# haltium_sysctrl register map
Vendor: Nordic Semiconductor; Series: nRFHaltium; File version: 1
Registers are 32-bit, read-write, reset 0x0 unless marked. A register's access mark holds for its fields unless they carry their own. Offsets are from the block's base; [hi:lo] are bit positions; {n}, {i} and the like mark numbered series.

## RAMC110_S — RAM Controller 0
Base 0x5F083000
Same registers: RAMC111_S 0x5F084000, RAMC112_S 0x5F08A000, RAMC113_S 0x5F08B000, RAMC120_S 0x5F8C3000, RAMC121_S 0x5F8C4000, RAMC130_S 0x5F903000, RAMC131_S 0x5F904000
0x500 WAITSTATES — Waitstates for read operations.
  [0] WAITSTATES — Number of waitstates for a read from the RAM.

## SHA3_S — CRACEN
Base 0x5F088000
0x100 EVENTS_CRYPTOMASTER — Event indicating that interrupt triggered at Cryptomaster
  [0] EVENTS_CRYPTOMASTER
    0=NotGenerated (Event not generated); 1=Generated (Event generated)
0x300 INTEN — Enable or disable interrupt
  [0] CRYPTOMASTER — Enable or disable interrupt for event CRYPTOMASTER
    0=Disabled; 1=Enabled
0x304 INTENSET — Enable interrupt
  [0] CRYPTOMASTER — Write '1' to enable interrupt for event CRYPTOMASTER
    on read: 0=Disabled (Read: Disabled); 1=Enabled (Read: Enabled) | on write: 1=Set (Enable)
0x308 INTENCLR — Disable interrupt
  [0] CRYPTOMASTER — Write '1' to disable interrupt for event CRYPTOMASTER
    on read: 0=Disabled (Read: Disabled); 1=Enabled (Read: Enabled) | on write: 1=Clear (Disable)
0x30C INTPEND ro — Pending interrupts
  [0] CRYPTOMASTER — Read pending status of interrupt for event CRYPTOMASTER
    on read: 0=NotPending (Read: Not pending); 1=Pending (Read: Pending)
0x400 ENABLE — Enable CRACEN peripheral modules.
  [0] CRYPTOMASTER — Enable cryptomaster
    0=Disabled (Cryptomaster disabled.); 1=Enabled (Cryptomaster enabled.)

## PCGCS110_S — PCGCSlave 0
Base 0x5F08E000
Same registers: PCGCS120_S 0x5F8EA000, PCGCS121_S 0x5F8EB000, PCGCS122_S 0x5F8EC000, PCGCS130_S 0x5F90E000, PCGCS131_S 0x5F93C000, PCGCS132_S 0x5F94E000, PCGCS133_S 0x5F98E000, PCGCS134_S 0x5F99E000, PCGCS135_S 0x5F9AE000, PCGCS136_S 0x5F9BE000, PCGCS137_S 0x5F9CE000, PCGCS138_S 0x5F9DE000
0x78 TRIGZEROPENALTY — Trigger zero penalty
  [0] TRIGGER
    1=Enable (Trigger zero penalty)
0x7C TRIGFULLPENALTY — Trigger full penalty
  [0] TRIGGER
    1=Enable (Trigger full penalty)
{0xC00+4i} PENALTY[{i}] (i=0..1) — Description collection: Penalty level for power/clock pair n
  [7:0] PENALTY — Penalty level
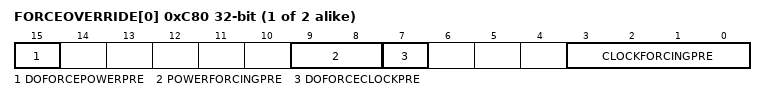
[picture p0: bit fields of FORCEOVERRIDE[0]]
{0xC80+4i} FORCEOVERRIDE[{i}] (i=0..1) — Description collection: Force override of power/clock pair n
  [15] DOFORCEPOWERPRE, [9:8] POWERFORCINGPRE, [7] DOFORCECLOCKPRE, [3:0] CLOCKFORCINGPRE

## PCGCM110_S — PCGC Master 0
Base 0x5F08F000
Same registers: PCGCM120_S 0x5F8CF000, PCGCM121_S 0x5F8ED000, PCGCM130_S 0x5F93D000, PCGCM131_S 0x5F93F000, PCGCM132_S 0x5F94F000, PCGCM133_S 0x5F98F000, PCGCM134_S 0x5F99F000, PCGCM135_S 0x5F9AF000, PCGCM136_S 0x5F9BF000, PCGCM137_S 0x5F9CF000, PCGCM138_S 0x5F9DF000
{0xE0+4i} SETPWRCONTHRESHOLDBASE[{i}] (i=0..2) — Description collection: Set power consumption threshold base for power source / regulator n
  [3:0] SETPWRCONTHRESHOLDBASE
{0x100+4i} SETPOWERCONSUMPTIONBASE[{i}] (i=0..1) — Description collection: Set power consumption base for power/clock pair n
  [3:0] POWERREQUIREMENT
0xC00 UNLOCKBACKDOORS
  [15:0] UNLOCKBACKDOORS — Write: 0x00009375 to lock/unlock backdoors Read: 0x00000001 if backdoors is enabled Read: 0x00000000 if backdoors is disabled
0xC04 ENABLEPOWERREGFORCE
  [2:0] ENABLEPOWERREGFORCE
0xC08 POWERREGFORCE — Force reg
  [2:0] POWERREGFORCEREG
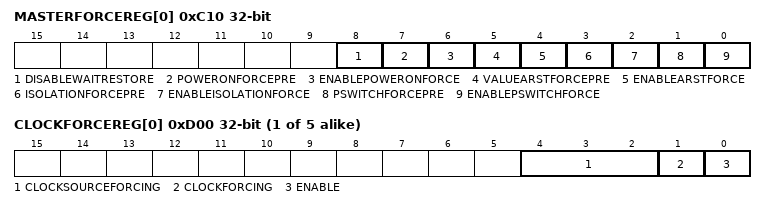
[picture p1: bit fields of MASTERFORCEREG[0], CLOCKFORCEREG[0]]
{0xC10+4i} MASTERFORCEREG[{i}] (i=0..0) — Description collection: Force reg
  [8] DISABLEWAITRESTORE — Turn off waiting for arst deactivation before retention restore
    1=Disable (Turn off waiting for arst deactivation before retention restore); 0=Enable (Wait for arst deactivation before retention restore)
  [7] POWERONFORCEPRE
  [6] ENABLEPOWERONFORCE
  [5] VALUEARSTFORCEPRE
  [4] ENABLEARSTFORCE
  [3] ISOLATIONFORCEPRE
  [2] ENABLEISOLATIONFORCE
  [1] PSWITCHFORCEPRE
  [0] ENABLEPSWITCHFORCE
{0xD00+4i} CLOCKFORCEREG[{i}] (i=0..4) — Description collection: Force clock n
  [4:2] CLOCKSOURCEFORCING
  [1] CLOCKFORCING
  [0] ENABLE — Enable clock forcing
